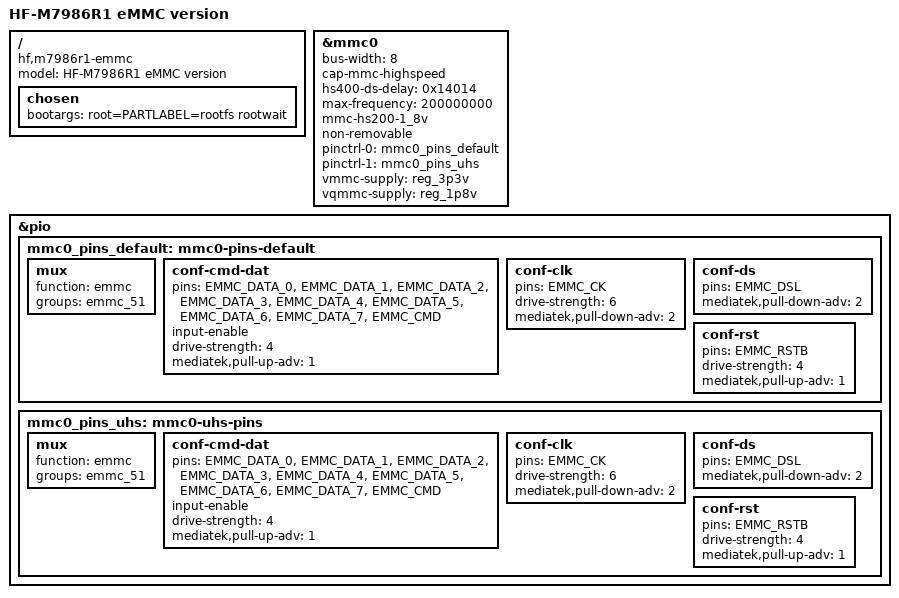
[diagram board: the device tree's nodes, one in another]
// SPDX-License-Identifier: GPL-2.0-or-later OR MIT

/dts-v1/;
#include "mt7986a-hf-m7986r1.dtsi"

/ {
	model = "HF-M7986R1 eMMC version";
	compatible = "hf,m7986r1-emmc", "mediatek,mt7986a";

	chosen {
		bootargs = "root=PARTLABEL=rootfs rootwait";
	};
};

&mmc0 {
	bus-width = <8>;
	cap-mmc-highspeed;
	hs400-ds-delay = <0x14014>;
	max-frequency = <200000000>;
	mmc-hs200-1_8v;
	non-removable;
	pinctrl-names = "default", "state_uhs";
	pinctrl-0 = <&mmc0_pins_default>;
	pinctrl-1 = <&mmc0_pins_uhs>;
	vmmc-supply = <&reg_3p3v>;
	vqmmc-supply = <&reg_1p8v>;
	status = "okay";
};

&pio {
	mmc0_pins_default: mmc0-pins-default {
		mux {
			function = "emmc";
			groups = "emmc_51";
		};
		conf-cmd-dat {
			pins = "EMMC_DATA_0", "EMMC_DATA_1", "EMMC_DATA_2",
			       "EMMC_DATA_3", "EMMC_DATA_4", "EMMC_DATA_5",
			       "EMMC_DATA_6", "EMMC_DATA_7", "EMMC_CMD";
			input-enable;
			drive-strength = <4>;
			mediatek,pull-up-adv = <1>;
		};
		conf-clk {
			pins = "EMMC_CK";
			drive-strength = <6>;
			mediatek,pull-down-adv = <2>;
		};
		conf-ds {
			pins = "EMMC_DSL";
			mediatek,pull-down-adv = <2>;
		};
		conf-rst {
			pins = "EMMC_RSTB";
			drive-strength = <4>;
			mediatek,pull-up-adv = <1>;
		};
	};

	mmc0_pins_uhs: mmc0-uhs-pins {
		mux {
			function = "emmc";
			groups = "emmc_51";
		};
		conf-cmd-dat {
			pins = "EMMC_DATA_0", "EMMC_DATA_1", "EMMC_DATA_2",
			       "EMMC_DATA_3", "EMMC_DATA_4", "EMMC_DATA_5",
			       "EMMC_DATA_6", "EMMC_DATA_7", "EMMC_CMD";
			input-enable;
			drive-strength = <4>;
			mediatek,pull-up-adv = <1>;
		};
		conf-clk {
			pins = "EMMC_CK";
			drive-strength = <6>;
			mediatek,pull-down-adv = <2>;
		};
		conf-ds {
			pins = "EMMC_DSL";
			mediatek,pull-down-adv = <2>;
		};
		conf-rst {
			pins = "EMMC_RSTB";
			drive-strength = <4>;
			mediatek,pull-up-adv = <1>;
		};
	};
};
